# STM32G544 register map
File version: 2.0.0
CPU: CM33 r0p4, little endian, MPU, FPU, 4 interrupt priority bits
Registers are 32-bit, read-write, reset 0x0 unless marked. A register's access mark holds for its fields unless they carry their own. Offsets are from the block's base; [hi:lo] are bit positions; {n}, {i} and the like mark numbered series; 'fields as' and 'values as' point back to an identical list.

## RCC — RCC address block description
Base 0x44020C00
Same registers: RCC_S 0x54020C00
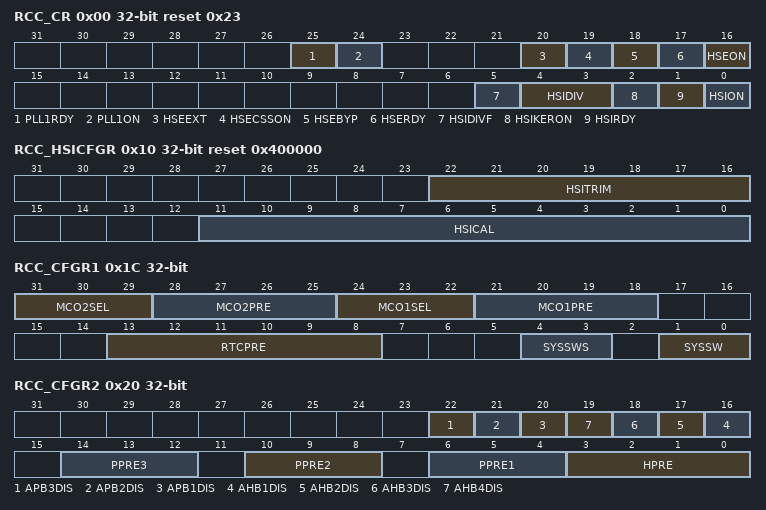
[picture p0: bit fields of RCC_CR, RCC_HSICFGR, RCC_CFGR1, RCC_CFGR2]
0x00 RCC_CR reset 0x23 — RCC clock control register
  [25] PLL1RDY ro — PLL1 clock ready flag
    0=PLL1 unlocked (default after reset); 1=PLL1 locked
  [24] PLL1ON — PLL1 enable
    0=PLL1 OFF (default after reset); 1=PLL1 ON
  [20] HSEEXT — external high speed clock type in Bypass mode
    0=HSE in analog mode (default after reset); 1=HSE in digital mode
  [19] HSECSSON — HSE clock security system enable
    0=CSS on HSE OFF (clock detector OFF) (default after reset); 1=CSS on HSE ON (clock detector ON if the HSE oscillator is stable, OFF if not)
  [18] HSEBYP — HSE clock bypass
    0=HSE oscillator not bypassed (default after reset); 1=HSE oscillator bypassed with an external clock
  [17] HSERDY ro — HSE clock ready flag
    0=HSE clock is not ready (default after reset); 1=HSE clock is ready
  [16] HSEON — HSE clock enable
    0=HSE is OFF (default after reset); 1=HSE is ON
  [5] HSIDIVF ro — HSI divider flag
    0=new division ratio not yet propagated to hsi_ck , hsi_ker_ck (default after reset); 1=hsi_ck, hsi_ker_ck clock frequency reflects the new HSIDIV value (default register value when the clock setting is completed)
  [4:3] HSIDIV — HSI clock divider
    0=division by 1, hsi_ck, hsi_ker_ck = 64 MHz (default after reset); 1=division by 2, hsi_ck, hsi_ker_ck = 32 MHz; 2=division by 4, hsi_ck, hsi_ker_ck = 16 MHz; 3=division by 8, hsi_ck, hsi_ker_ck = 8 MHz
  [2] HSIKERON — HSI clock enable in Stop mode
    0=no effect on HSI (default after reset); 1=HSI is forced to ON even in Stop mode
  [1] HSIRDY ro — HSI clock ready flag
    0=HSI clock is not ready (default after reset); 1=HSI clock is ready
  [0] HSION — HSI clock enable
    0=HSI is OFF; 1=HSI is ON (default after reset)
0x10 RCC_HSICFGR reset 0x400000 (reset mask 0xFFFFF000) — RCC HSI calibration register
  [22:16] HSITRIM — HSI clock trimming
  [11:0] HSICAL ro — HSI clock calibration
0x1C RCC_CFGR1 — RCC clock configuration register1
  [31:29] MCO2SEL — microcontroller clock output 2
    0=system clock selected (sys_ck) (default after reset); 1=PLL2 oscillator clock selected (pll2_p_ck); 2=HSE clock selected (hse_ck); 3=PLL1 clock selected (pll1_p_ck); 4=LSI clock selected (lsi_ck)
  [28:25] MCO2PRE — MCO2 prescaler
    0=prescaler disabled, no clock output on MCO2 (default after reset); 1=division by 1 (bypass); 2=division by 2; 3=division by 3; 4=division by 4; 15=division by 15
  [24:22] MCO1SEL — Microcontroller clock output 1
    0=HSI clock selected (hsi_ck) (default after reset); 1=LSE oscillator clock selected (lse_ck); 2=HSE clock selected (hse_ck); 3=PLL1 clock selected (pll1_q_ck); 4=HSI48 clock selected (hsi48_ker_ck)
  [21:18] MCO1PRE — MCO1 prescaler
    0=prescaler disabled, no clock output on MCO1 (default after reset); 1=division by 1 (bypass); 2=division by 2; 3=division by 3; 4=division by 4; 15=division by 15
  [13:8] RTCPRE — HSE division factor for RTC clock
    0=no clock (default after reset); 1=no clock; 2=HSE/2; 3=HSE/3; 4=HSE/4; 62=HSE/62; 63=HSE/63
  [4:3] SYSSWS ro — system clock switch status
    0=HSI used as system clock (hsi_ck) (default after reset); 1=HSE used as system clock (hse_ck); 2=PLL1 used as system clock (pll1_p_ck)
  [1:0] SYSSW — system clock and trace clock switch
    0=HSI selected as system clock (hsi_ck) (default after reset); 1=HSE selected as system clock (hse_ck); 2=PLL1 selected as system clock (pll1_p_ck)
0x20 RCC_CFGR2 — RCC CPU domain clock configuration register 2
  [22] APB3DIS — APB3 clock disable value.
    0=APB3 clock enabled, distributed to peripherals according to their dedicated clock enable control bits; 1=APB3 clock disabled
  [21] APB2DIS — APB2 clock disable value
    0=APB2 clock enabled, distributed to peripherals according to their dedicated clock enable control bits; 1=APB2 clock disabled
  [20] APB1DIS — APB1 clock disable value
    0=APB1 clock enabled, distributed to peripherals according to their dedicated clock enable control bits; 1=APB1 clock disabled
  [n+15] AHB{n}DIS (n=1..4) — AHB{n} clock disable
    0=AHB{n} clock enabled, distributed to peripherals according to their dedicated clock enable control bits; 1=AHB{n} clock disabled
  [14:12] PPRE3 — APB low-speed prescaler (APB3)
    4=rcc_pclk3 = rcc_hclk1 / 2; 5=rcc_pclk3 = rcc_hclk1 / 4; 6=rcc_pclk3 = rcc_hclk1 / 8; 7=rcc_pclk3 = rcc_hclk1 / 16
  [10:8] PPRE2 — APB high-speed prescaler (APB2)
    4=rcc_pclk2 = rcc_hclk1 / 2; 5=rcc_pclk2 = rcc_hclk1 / 4; 6=rcc_pclk2 = rcc_hclk1 / 8; 7=rcc_pclk2 = rcc_hclk1 / 16
  [6:4] PPRE1 — APB low-speed prescaler (APB1)
    4=rcc_pclk1 = rcc_hclk1 / 2; 5=rcc_pclk1 = rcc_hclk1 / 4; 6=rcc_pclk1 = rcc_hclk1 / 8; 7=rcc_pclk1 = rcc_hclk1 / 16
  [3:0] HPRE — AHB prescaler
    8=rcc_hclk = sys_ck / 2; 9=rcc_hclk = sys_ck / 4; 10=rcc_hclk = sys_ck / 8; 11=rcc_hclk = sys_ck / 16; 12=rcc_hclk = sys_ck / 64; 13=rcc_hclk = sys_ck / 128; 14=rcc_hclk = sys_ck / 256; 15=rcc_hclk = sys_ck / 512
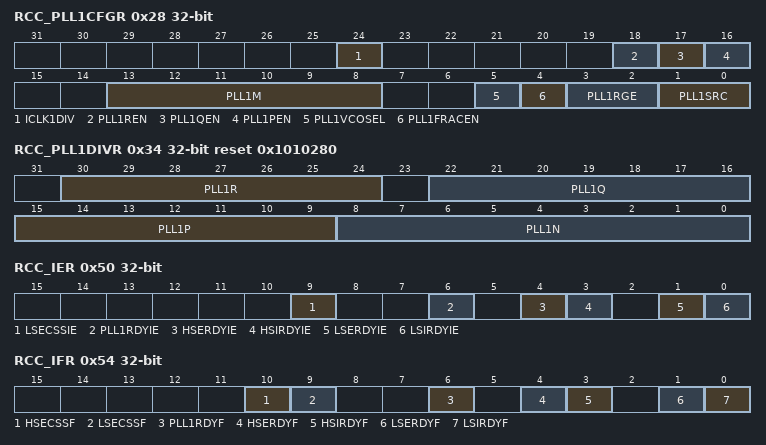
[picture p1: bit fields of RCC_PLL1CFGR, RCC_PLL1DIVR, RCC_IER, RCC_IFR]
0x28 RCC_PLL1CFGR — RCC PLL clock source selection register
  [24] ICLK1DIV — Intermediate Clock 1 division
    0=Intermediate clock 1 division ratio is 5 (default after reset); 1=Intermediate clock 1 division ratio is 3
  [18] PLL1REN — PLL1 DIVR and ICLK1 divider output enable
    0=pll1_r_ck and ic1_ck outputs disabled (default after reset); 1=pll1_r_ck and ic1_ck outputs enabled
  [17] PLL1QEN — PLL1 DIVQ divider output enable
    0=pll1_q_ck output disabled (default after reset); 1=pll1_q_ck output enabled
  [16] PLL1PEN — PLL1 DIVP divider output enable
    0=pll1_p_ck output disabled (default after reset); 1=pll1_p_ck output enabled
  [13:8] PLL1M — prescaler for PLL1
    0=prescaler disabled (default after reset); 1=division by 1 (bypass); 2=division by 2; 3=division by 3; 32=division by 32; 63=division by 63
  [5] PLL1VCOSEL — PLL1 VCO selection
    0=wide VCO range: 128 to 560 MHz (default after reset); 1=medium VCO range: 150 to 420 MHz
  [4] PLL1FRACEN — PLL1 fractional latch enable
  [3:2] PLL1RGE — PLL1 input frequency range
    0=PLL1 input (ref1_ck) clock range frequency between 1 and 2 MHz (default after reset); 1=PLL1 input (ref1_ck) clock range frequency between 2 and 4 MHz; 2=PLL1 input (ref1_ck) clock range frequency between 4 and 8 MHz; 3=PLL1 input (ref1_ck) clock range frequency between 8 and 16 MHz
  [1:0] PLL1SRC — PLL1M and PLLs clock source selection
    0=no clock sent to PLL1M divider and PLL1 (default after reset); 1=HSI selected as PLL clock (hsi_ck); 2=HSE selected as PLL clock (hse_ck); 3=no clock sent to PLL1M divider and PLL1
0x34 RCC_PLL1DIVR reset 0x1010280 — RCC PLL1 dividers register
  [30:24] PLL1R — PLL1 DIVR division factor
    0=pll1_r_ck = vco1_ck / 1; 1=pll1_r_ck = vco1_ck / 2 (default after reset); 2=pll1_r_ck = vco1_ck / 3; 3=pll1_r_ck = vco1_ck / 4; 127=pll1_r_ck = vco1_ck / 128
  [22:16] PLL1Q — PLL1 DIVQ division factor
    0=pll1_q_ck = vco1_ck; 1=pll1_q_ck = vco1_ck / 2 (default after reset); 2=pll1_q_ck = vco1_ck / 3; 3=pll1_q_ck = vco1_ck / 4; 127=pll1_q_ck = vco1_ck / 128
  [15:9] PLL1P — PLL1 DIVP division factor
    0=Not allowed; 1=pll1_p_ck = vco1_ck / 2 (default after reset); 2=Not allowed; 3=pll1_p_ck = vco1_ck / 4; 127=pll1_p_ck = vco1_ck / 128
  [8:0] PLL1N — Multiplication factor for PLL1VCO
    3=PLL1N = 4; 4=PLL1N = 5; 5=PLL1N = 6; 128=PLL1N = 129 (default after reset); 0x1FF=PLL1N = 512
0x38 RCC_PLL1FRACR — RCC PLL1 fractional divider register
  [15:3] PLL1FRACN — fractional part of the multiplication factor for PLL1 VCO
0x50 RCC_IER — RCC Interrupt enable register
  [9] LSECSSIE — LSE clock security system interrupt enable
    0=LSE CSS interrupt disabled (default after reset); 1=LSE CSS interrupt enabled
  [6] PLL1RDYIE — PLL1 ready interrupt enable
    0=PLL1 lock interrupt disabled (default after reset); 1=PLL1 lock interrupt enabled
  [4] HSERDYIE — HSE ready interrupt enable
    0=HSE ready interrupt disabled (default after reset); 1=HSE ready interrupt enabled
  [3] HSIRDYIE — HSI ready interrupt enable
    0=HSI ready interrupt disabled (default after reset); 1=HSI ready interrupt enabled
  [1] LSERDYIE — LSE ready interrupt enable
    0=LSE ready interrupt disabled (default after reset); 1=LSE ready interrupt enabled
  [0] LSIRDYIE — LSI ready interrupt enable
    0=LSI ready interrupt disabled (default after reset); 1=LSI ready interrupt enabled
0x54 RCC_IFR ro — RCC Interrupt flag register
  [10] HSECSSF — HSE clock security system interrupt flag
    0=no clock security interrupt caused by HSE clock failure (default after reset); 1=clock security interrupt caused by HSE clock failure
  [9] LSECSSF — LSE clock security system interrupt flag
    values as HSECSSF
  [6] PLL1RDYF — PLL1 ready interrupt flag
    0=no clock ready interrupt caused by PLL1 lock (default after reset); 1=clock ready interrupt caused by PLL1 lock
  [4] HSERDYF — HSE ready interrupt flag
    0=no clock ready interrupt caused by the HSE (default after reset); 1=clock ready interrupt caused by the HSE
  [3] HSIRDYF — HSI ready interrupt flag
    0=no clock ready interrupt caused by the HSI (default after reset); 1=clock ready interrupt caused by the HSI
  [1] LSERDYF — LSE ready interrupt flag
    0=no clock ready interrupt caused by the LSE (default after reset); 1=clock ready interrupt caused by the LSE
  [0] LSIRDYF — LSI ready interrupt flag
    0=no clock ready interrupt caused by the LSI (default after reset); 1=clock ready interrupt caused by the LSI
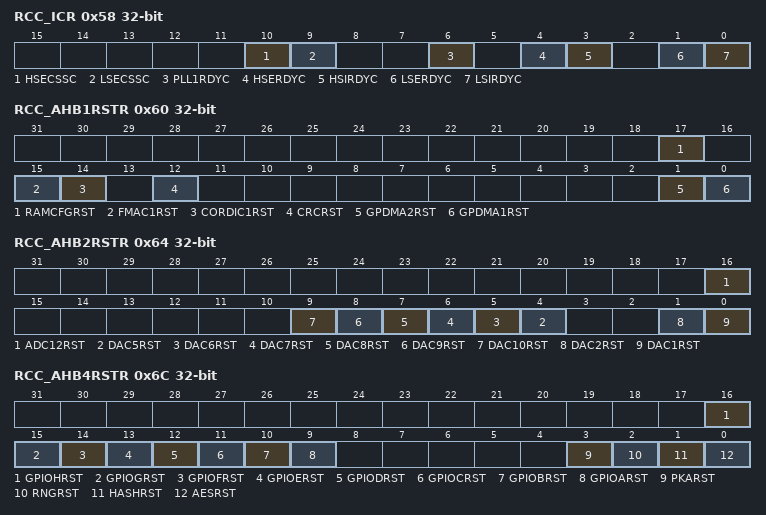
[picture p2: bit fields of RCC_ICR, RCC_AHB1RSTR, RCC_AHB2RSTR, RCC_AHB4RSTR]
0x58 RCC_ICR — RCC Interrupt clear register
  [10] HSECSSC — HSE clock security system interrupt clear
    0=HSECSSF no effect (default after reset); 1=HSECSSF cleared
  [9] LSECSSC — LSE clock security system interrupt clear
    0=LSECSSF no effect (default after reset); 1=LSECSSF cleared
  [6] PLL1RDYC — PLL1 ready interrupt clear
    0=PLL1RDYF no effect (default after reset); 1=PLL1RDYF cleared
  [4] HSERDYC — HSE ready interrupt clear
    0=HSERDYF no effect (default after reset); 1=HSERDYF cleared
  [3] HSIRDYC — HSI ready interrupt clear
    0=HSIRDYF no effect (default after reset); 1=HSIRDYF cleared
  [1] LSERDYC — LSE ready interrupt clear
    0=LSERDYF no effect (default after reset); 1=LSERDYF cleared
  [0] LSIRDYC — LSI ready interrupt clear
    0=LSIRDYF no effect (default after reset); 1=LSIRDYF cleared
0x60 RCC_AHB1RSTR — RCC AHB1 reset register
  [17] RAMCFGRST — RAMCFG block reset
    0=does not reset RAMCFG block (default after reset); 1=resets RAMCFG block
  [15] FMAC1RST — FMAC1 block reset
    0=does not reset FMAC1 block (default after reset); 1=resets FMAC1 block
  [14] CORDIC1RST — CORDIC1 block reset
    0=does not reset CORDIC1 block (default after reset); 1=resets CORDIC1 block
  [12] CRCRST — CRC block reset Set and cleared by software.
    0=does not reset CRC block (default after reset); 1=resets CRC block
  [1] GPDMA2RST — GPDMA2 block reset
    0=does not reset GPDMA2 block (default after reset); 1=resets GPDMA2 block
  [0] GPDMA1RST — GPDMA1 block reset
    0=does not reset GPDMA1 block (default after reset); 1=resets GPDMA1 block
0x64 RCC_AHB2RSTR — RCC AHB2 peripheral reset register
  [16] ADC12RST — ADC1 and 2 blocks reset
    0=does not reset ADC1 and 2 blocks (default after reset); 1=resets ADC1 and 2 blocks
  [n-1] DAC{n}RST (n=5..10) — DAC{n} block reset
    0=does not reset DAC{n} block (default after reset); 1=resets DAC{n} block
  [1] DAC2RST — DAC2 block reset
    0=does not reset DAC2 block (default after reset); 1=resets DAC2 block
  [0] DAC1RST — DAC1 block reset
    0=does not reset DAC1 block (default after reset); 1=resets DAC1 block
0x6C RCC_AHB4RSTR — RCC AHB4 peripheral reset register
  [16] GPIOHRST — GPIOH block reset
    0=does not reset the GPIOH block (default after reset); 1=resets the GPIOH block
  [15] GPIOGRST — GPIOG block reset
    0=does not reset the GPIOG block (default after reset); 1=resets the GPIOG block
  [14] GPIOFRST — GPIOF block reset
    0=does not reset the GPIOF block (default after reset); 1=resets the GPIOF block
  [13] GPIOERST — GPIOE block reset
    0=does not reset the GPIOE block (default after reset); 1=resets the GPIOE block
  [12] GPIODRST — GPIOD block reset
    0=does not reset the GPIOD block (default after reset); 1=resets the GPIOD block
  [11] GPIOCRST — GPIOC block reset
    0=does not reset the GPIOC block (default after reset); 1=resets the GPIOC block
  [10] GPIOBRST — GPIOB block reset
    0=does not reset the GPIOB block (default after reset); 1=resets the GPIOB block
  [9] GPIOARST — GPIOA block reset
    0=does not reset the GPIOA block (default after reset); 1=resets the GPIOA block
  [3] PKARST — PKA block reset
    0=does not reset PKA block (default after reset); 1=resets PKA block
  [2] RNGRST — RNG block reset
    0=does not reset RNG block (default after reset); 1=resets RNG block
  [1] HASHRST — HASH block reset
    0=does not reset HASH block (default after reset); 1=resets HASH block
  [0] AESRST — AES block reset
    0=does not reset AES block (default after reset); 1=resets AES block
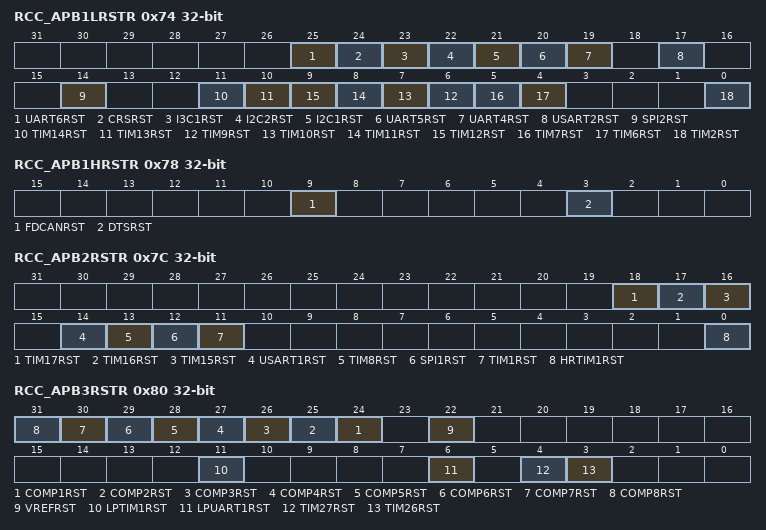
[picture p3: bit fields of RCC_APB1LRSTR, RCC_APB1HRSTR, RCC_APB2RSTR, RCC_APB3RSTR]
0x74 RCC_APB1LRSTR — RCC APB1 peripheral low reset register
  [25] UART6RST — UART6 block reset
    0=does not reset the UART6 block (default after reset); 1=resets the UART6 block
  [24] CRSRST — CRS block reset
    0=does not reset the CRS block (default after reset); 1=resets the CRS block
  [23] I3C1RST — I3C1 block reset
    0=does not reset the I3C1 block (default after reset); 1=resets the I3C1 block
  [22] I2C2RST — I2C2 block reset
    0=does not reset the I2C2 block (default after reset); 1=resets the I2C2 block
  [21] I2C1RST — I2C1 block reset
    0=does not reset the I2C1 block (default after reset); 1=resets the I2C1 block
  [20] UART5RST — UART5 block reset
    0=does not reset the UART5 block (default after reset); 1=resets the UART5 block
  [19] UART4RST — UART4 block reset
    0=does not reset the UART4 block (default after reset); 1=resets the UART4 block
  [17] USART2RST — USART2 block reset
    0=does not reset the USART2 block (default after reset); 1=resets the USART2 block
  [14] SPI2RST — SPI2 block reset
    0=does not reset the SPI2 block (default after reset); 1=resets the SPI2 block
  [11] TIM14RST — TIM14 block reset
    0=does not reset the TIM14 block (default after reset); 1=resets the TIM14 block
  [10] TIM13RST — TIM13 block reset
    0=does not reset the TIM13 block (default after reset); 1=resets the TIM13 block
  [n-3] TIM{n}RST (n=9..12) — TIM12 block reset
    0=does not reset the TIM12 block (default after reset); 1=resets the TIM12 block
  [5] TIM7RST — TIM7 block reset
    0=does not reset the TIM7 block (default after reset); 1=resets the TIM7 block
  [4] TIM6RST — TIM6 block reset
    0=does not reset the TIM6 block (default after reset); 1=resets the TIM6 block
  [0] TIM2RST — TIM2 block reset
    0=does not reset the TIM2 block (default after reset); 1=resets the TIM2 block
0x78 RCC_APB1HRSTR — RCC APB1 peripheral high reset register
  [9] FDCANRST — FDCAN1, FDCAN2 and FDCAN3 blocks reset
    0=does not reset the FDCAN1, FDCAN2 and FDCAN3 blocks (default after reset); 1=resets the FDCAN1, FDCAN2 and FDCAN3 blocks
  [3] DTSRST — DTS block reset
    0=does not reset the DTS block (default after reset); 1=resets the DTS block
0x7C RCC_APB2RSTR — RCC APB2 peripheral reset register
  [18] TIM17RST — TIM17 block reset
    0=does not reset the TIM17 block (default after reset); 1=resets the TIM17 block
  [17] TIM16RST — TIM16 block reset
    0=does not reset the TIM16 block (default after reset); 1=resets the TIM16 block
  [16] TIM15RST — TIM15 block reset
    0=does not reset the TIM15 block (default after reset); 1=resets the TIM15 block
  [14] USART1RST — USART1 block reset
    0=does not reset the USART1 block (default after reset); 1=resets the USART1 block
  [13] TIM8RST — TIM8 block reset
    0=does not reset the TIM8 block (default after reset); 1=resets the TIM8 block
  [12] SPI1RST — SPI1 block reset
    0=does not reset the SPI1 block (default after reset); 1=resets the SPI1 block
  [11] TIM1RST — TIM1 block reset
    0=does not reset the TIM1 block (default after reset); 1=resets the TIM1 block
  [0] HRTIM1RST — HRTIM1 block reset
    0=does not reset the HRTIM1 block (default after reset); 1=resets the HRTIM1 block
0x80 RCC_APB3RSTR — RCC APB3 peripheral reset register
  [n+23] COMP{n}RST (n=1..8) — COMP{n} block reset
    0=does not reset the COMP{n} block (default after reset); 1=resets the COMP{n} block
  [22] VREFRST — VREFBUF block reset
    0=does not reset the VREFBUF block (default after reset); 1=resets the VREFBUF block
  [11] LPTIM1RST — LPTIM1 block reset
    0=does not reset the LPTIM1 block (default after reset); 1=resets the LPTIM1 block
  [6] LPUART1RST — LPUART1 block reset
    0=does not reset the LPUART1 block (default after reset); 1=resets the LPUART1 block
  [4] TIM27RST — TIM27 block reset
    0=does not reset the TIM27 block (default after reset); 1=resets the TIM27 block
  [3] TIM26RST — TIM26 block reset
    0=does not reset the TIM26 block (default after reset); 1=resets the TIM26 block
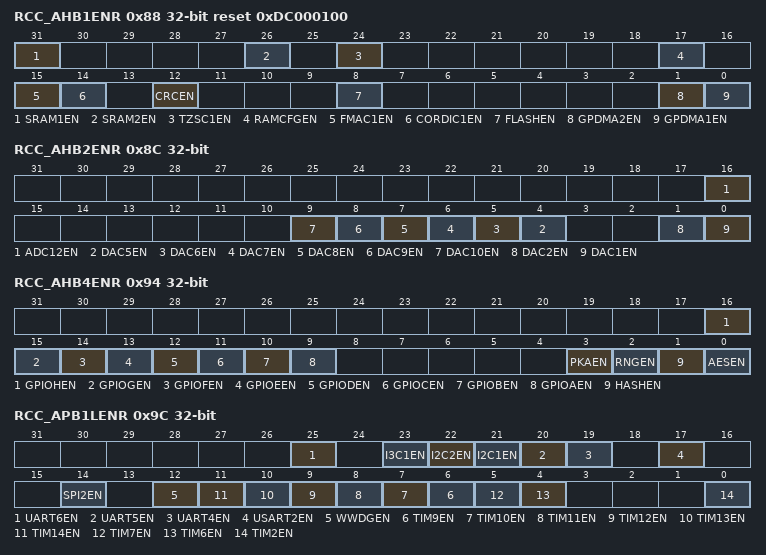
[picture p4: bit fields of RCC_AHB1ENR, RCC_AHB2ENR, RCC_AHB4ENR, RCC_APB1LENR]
0x88 RCC_AHB1ENR reset 0xDC000100 — RCC AHB1 peripheral clock enable register
  [31] SRAM1EN — SRAM1 clock enable
    0=SRAM1 clock disabled; 1=SRAM1 clock enabled (default after reset)
  [26] SRAM2EN — SRAM2 clock enable
    0=SRAM2 clock disabled; 1=SRAM2 clock enabled (default after reset)
  [24] TZSC1EN — TZSC1 clock enable
    0=TZSC1 peripheral clock disabled (default after reset); 1=TZSC1 peripheral clock enabled
  [17] RAMCFGEN — RAMCFG clock enable
    0=RAMCFG peripheral clock disabled (default after reset); 1=RAMCFG peripheral clock enabled
  [15] FMAC1EN — FMAC1 clock enable
    0=FMAC1 peripheral clock disabled (default after reset); 1=FMAC1 peripheral clock enabled
  [14] CORDIC1EN — CORDIC1 clock enable
    0=CORDIC1 peripheral clock disabled (default after reset); 1=CORDIC1 peripheral clock enable
  [12] CRCEN — CRC clock enable
    0=CRC peripheral clock disabled (default after reset); 1=CRC peripheral clock enabled
  [8] FLASHEN — Flash interface clock enable
    0=FLASH interface clock disabled; 1=FLASH interface clock enabled (default after reset)
  [1] GPDMA2EN — GPDMA2 clock enable
    0=GPDMA2 peripheral clock disabled (default after reset); 1=GPDMA2 peripheral clock enabled
  [0] GPDMA1EN — GPDMA1 clock enable
    0=GPDMA1 peripheral clock disabled (default after reset); 1=GPDMA1 peripheral clock enabled
0x8C RCC_AHB2ENR — RCC AHB2 peripheral clock enable register
  [16] ADC12EN — ADC1 and ADC2 peripheral clocks enable
    0=ADC1 and ADC2 peripheral clocks disabled (default after reset); 1=ADC1 and ADC2 peripheral clocks enabled
  [n-1] DAC{n}EN (n=5..10) — DAC{n} clock enable
    0=DAC{n} peripheral clock disabled (default after reset); 1=DAC{n} peripheral clock enabled
  [1] DAC2EN — DAC2 clock enable
    0=DAC2 peripheral clock disabled (default after reset); 1=DAC2 peripheral clock enabled
  [0] DAC1EN — DAC1 clock enable
    0=DAC1 peripheral clock disabled (default after reset); 1=DAC1 peripheral clock enabled
0x90 RCC_AHB3ENR — RCC AHB3 peripheral clock enable register
  [21] DBGCKEN — DBG clock enable
    0=DBG peripheral clock disabled (default after reset); 1=DBG peripheral clock enabled
0x94 RCC_AHB4ENR — RCC AHB4 peripheral clock enable register
  [16] GPIOHEN — GPIOH clock enable
    0=GPIOH peripheral clock disabled (default after reset); 1=GPIOH peripheral clock enabled
  [15] GPIOGEN — GPIOG clock enable
    0=GPIOG peripheral clock disabled (default after reset); 1=GPIOG peripheral clock enabled
  [14] GPIOFEN — GPIOF clock enable
    0=GPIOF peripheral clock disabled (default after reset); 1=GPIOF peripheral clock enabled
  [13] GPIOEEN — GPIOE clock enable
    0=GPIOE peripheral clock disabled (default after reset); 1=GPIOE peripheral clock enabled
  [12] GPIODEN — GPIOD clock enable
    0=GPIOD peripheral clock disabled (default after reset); 1=GPIOD peripheral clock enabled
  [11] GPIOCEN — GPIOC clock enable
    0=GPIOC peripheral clock disabled (default after reset); 1=GPIOC peripheral clock enabled
  [10] GPIOBEN — GPIOB clock enable
    0=GPIOB peripheral clock disabled (default after reset); 1=GPIOB peripheral clock enabled
  [9] GPIOAEN — GPIOA clock enable
    0=GPIOA peripheral clock disabled (default after reset); 1=GPIOA peripheral clock enabled
  [3] PKAEN — PKA clock enable
    0=PKA peripheral clock disabled (default after reset); 1=PKA peripheral clock enabled
  [2] RNGEN — RNG clock enable
    0=RNG peripheral clock disabled (default after reset); 1=RNG peripheral clock enabled
  [1] HASHEN — HASH clock enable
    0=HASH peripheral clock disabled (default after reset); 1=HASH peripheral clock enabled
  [0] AESEN — AES clock enable
    0=AES peripheral clock disabled (default after reset); 1=AES peripheral clock enabled
0x9C RCC_APB1LENR — RCC APB1 peripheral clock enable register
  [25] UART6EN — UART6 clock enable
    0=UART6 peripheral clock disabled (default after reset); 1=UART6 peripheral clock enabled
  [23] I3C1EN — I3C1 clock enable
    0=I3C1 peripheral clock disabled (default after reset); 1=I3C1 peripheral clock enabled
  [22] I2C2EN — I2C2 clock enable
    0=I2C2 peripheral clock disabled (default after reset); 1=I2C2 peripheral clock enabled
  [21] I2C1EN — I2C1 clock enable
    0=I2C1 peripheral clock disabled (default after reset); 1=I2C1 peripheral clock enabled
  [20] UART5EN — UART5 clock enable
    0=UART5 peripheral clock disabled (default after reset); 1=UART5 peripheral clock enabled
  [19] UART4EN — UART4 clock enable
    0=UART4 peripheral clock disabled (default after reset); 1=UART4 peripheral clock enabled
  [17] USART2EN — USART2 clock enable
    0=USART2 peripheral clock disabled (default after reset); 1=USART2 peripheral clock enabled
  [14] SPI2EN — SPI2 clock enable
    0=SPI2 peripheral clock disabled (default after reset); 1=SPI2 peripheral clock enabled
  [12] WWDGEN — WWDG clock enable
    0=WWDG peripheral clock disabled (default after reset); 1=WWDG peripheral clock enabled
  [n-3] TIM{n}EN (n=9..14) — TIM{n} clock enable
    0=TIM{n} peripheral clock disabled (default after reset); 1=TIM{n} peripheral clock enabled
  [5] TIM7EN — TIM7 clock enable
    0=TIM7 peripheral clock disabled (default after reset); 1=TIM7 peripheral clock enabled
  [4] TIM6EN — TIM6 clock enable
    0=TIM6 peripheral clock disabled (default after reset); 1=TIM6 peripheral clock enabled
  [0] TIM2EN — TIM2 clock enable
    0=TIM2 peripheral clock disabled (default after reset); 1=TIM2 peripheral clock enabled
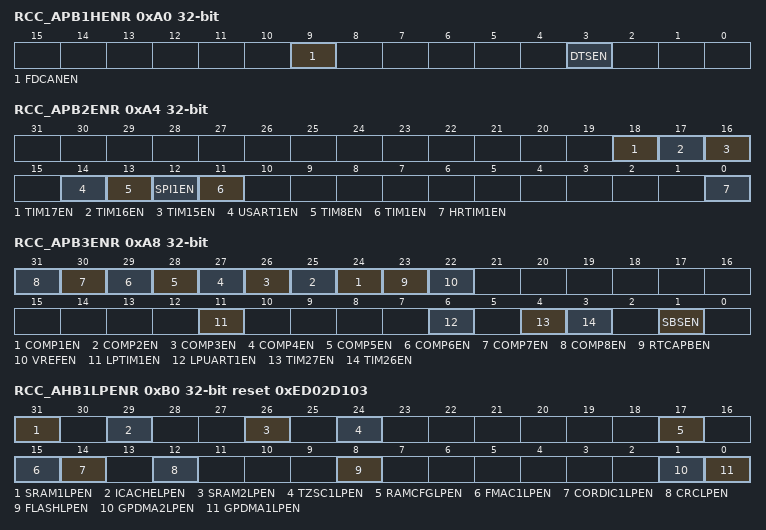
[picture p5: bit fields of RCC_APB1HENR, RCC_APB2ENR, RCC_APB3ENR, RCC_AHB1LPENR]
0xA0 RCC_APB1HENR — RCC APB1 peripheral clock enable register
  [9] FDCANEN — FDCAN1, FDCAN2 and FDCAN3 peripheral clock enable
    0=FDCAN1, FDCAN2 and FDCAN3 peripheral clock disabled (default after reset); 1=FDCAN1, FDCAN2 and FDCAN3 peripheral clock enabled
  [3] DTSEN — DTS clock enable
    0=DTS peripheral clock disabled (default after reset); 1=DTS peripheral clock enabled
0xA4 RCC_APB2ENR — RCC APB2 peripheral clock enable register
  [18] TIM17EN — TIM17 clock enable
    0=TIM17 peripheral clock disabled (default after reset); 1=TIM17 peripheral clock enabled
  [17] TIM16EN — TIM16 clock enable
    0=TIM16 peripheral clock disabled (default after reset); 1=TIM16 peripheral clock enabled
  [16] TIM15EN — TIM15 clock enable
    0=TIM15 peripheral clock disabled (default after reset); 1=TIM15 peripheral clock enabled
  [14] USART1EN — USART1 clock enable
    0=USART1 peripheral clock disabled (default after reset); 1=USART1 peripheral clock enabled
  [13] TIM8EN — TIM8 clock enable
    0=TIM8 peripheral clock disabled (default after reset); 1=TIM8 peripheral clock enabled
  [12] SPI1EN — SPI1 clock enable
    0=SPI1 peripheral clock disabled (default after reset); 1=SPI1 peripheral clock enabled
  [11] TIM1EN — TIM1 clock enable
    0=TIM1 peripheral clock disabled (default after reset); 1=TIM1 peripheral clock enabled
  [0] HRTIM1EN — HRTIM1 clock enable
    0=HRTIM1 peripheral clock disabled (default after reset); 1=HRTIM1 peripheral clock enabled
0xA8 RCC_APB3ENR — RCC APB3 peripheral clock enable register
  [n+23] COMP{n}EN (n=1..8) — COMP{n} clock enable
    0=COMP{n} clock disabled (default after reset); 1=COMP{n} clock enabled
  [23] RTCAPBEN — RTC APB interface clock enable
    0=RTC APB interface clock disabled (default after reset); 1=RTC APB interface clock enabled
  [22] VREFEN — VREFBUF clock enable
    0=VREFBUF peripheral clock disabled (default after reset); 1=VREFBUF peripheral clock enabled
  [11] LPTIM1EN — LPTIM1 clock enable
    0=LPTIM1 peripheral clock disabled (default after reset); 1=LPTIM1 peripheral clock enabled
  [6] LPUART1EN — LPUART1 clock enable
    0=LPUART1 peripheral clock disabled (default after reset); 1=LPUART1 peripheral clock enabled
  [4] TIM27EN — TIM27 clock enable
    0=TIM27 peripheral clock disabled (default after reset); 1=TIM27 peripheral clock enabled
  [3] TIM26EN — TIM26 clock enable
    0=TIM26 peripheral clock disabled (default after reset); 1=TIM26 peripheral clock enabled
  [1] SBSEN — SBS clock enable
    0=SBS peripheral clock disabled (default after reset); 1=SBS peripheral clock enabled
0xB0 RCC_AHB1LPENR reset 0xED02D103 — RCC AHB1 peripheral low-power clock enable register
  [31] SRAM1LPEN — SRAM1 clock enable in low power mode
    0=SRAM1 peripheral clock disabled in low power mode; 1=SRAM1 peripheral clock enabled in low power mode (default after reset)
  [29] ICACHELPEN — ICACHE clock enable in low power mode
    0=ICACHE peripheral clock disabled in low power mode; 1=ICACHE peripheral clock enabled in low power mode (default after reset)
  [26] SRAM2LPEN — SRAM2 clock enable in low power mode
    0=SRAM2 peripheral clock disabled in low power mode; 1=SRAM2 peripheral clock enabled in low power mode (default after reset)
  [24] TZSC1LPEN — TZSC1 clock enable in low power mode
    0=TZSC1 peripheral clock disabled in low power mode; 1=TZSC1 peripheral clock enabled in low power mode (default after reset)
  [17] RAMCFGLPEN — RAMCFG clock enable in low power mode
    0=RAMCFG peripheral clock disabled in low power mode; 1=RAMCFG peripheral clock enabled in low power mode (default after reset)
  [15] FMAC1LPEN — FMAC1 clock enable in low power mode
    0=FMAC1 peripheral clock disabled in low power mode; 1=FMAC1 peripheral clock enabled in low power mode (default after reset)
  [14] CORDIC1LPEN — CORDIC1 clock enable in low power mode
    0=CORDIC1 peripheral clock disabled in low power mode; 1=CORDIC1 peripheral clock enabled in low power mode (default after reset)
  [12] CRCLPEN — CRC clock enable in low power mode
    0=CRC peripheral clock disabled in low power mode; 1=CRC peripheral clock enabled in low power mode (default after reset)
  [8] FLASHLPEN — Flash memory interface clock enable in low-power mode
    0=Flash memory interface clock disabled in low power mode; 1=Flash memory interface clock enabled in low power mode (default after reset)
  [1] GPDMA2LPEN — GPDMA2 clock enable in low power mode
    0=GPDMA2 peripheral clock disabled in low power mode; 1=GPDMA2 peripheral clock enabled in low power mode (default after reset)
  [0] GPDMA1LPEN — GPDMA1 clock enable in low power mode
    0=GPDMA1 peripheral clock disabled in low power mode; 1=GPDMA1 peripheral clock enabled in low power mode (default after reset)
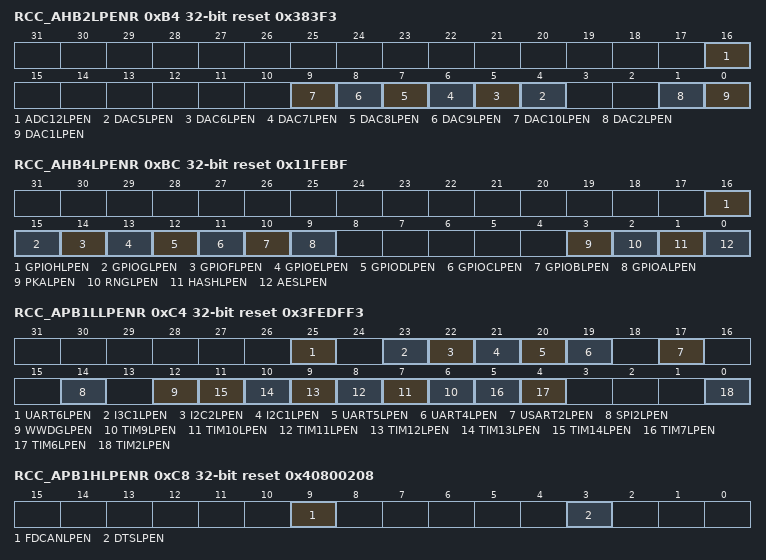
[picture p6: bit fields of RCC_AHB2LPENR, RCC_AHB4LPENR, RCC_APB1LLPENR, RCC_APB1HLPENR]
0xB4 RCC_AHB2LPENR reset 0x383F3 — RCC AHB2 peripheral low-power clock enable register
  [16] ADC12LPEN — ADC1 and 2 peripherals clock enable in low power mode
    0=ADC1 and 2 peripherals clock disabled in low power mode; 1=ADC1 and 2 peripherals clock enabled in low power mode (default after reset)
  [n-1] DAC{n}LPEN (n=5..10) — DAC{n} clock enable in low power mode
    0=DAC{n} peripheral clock disabled in low power mode; 1=DAC{n} peripheral clock enabled in low power mode (default after reset)
  [1] DAC2LPEN — DAC2 clock enable in low power mode
    0=DAC2 peripheral clock disabled in low power mode; 1=DAC2 peripheral clock enabled in low power mode (default after reset)
  [0] DAC1LPEN — DAC1 clock enable in low power mode
    0=DAC1 peripheral clock disabled in low power mode; 1=DAC1 peripheral clock enabled in low power mode (default after reset)
0xB8 RCC_AHB3LPENR reset 0x200000 — RCC AHB3 peripheral low-power clock enable register
  [21] DBGCKLPEN — DBG clock enable in low power mode
    0=DBG peripheral clock disabled in low power mode; 1=DBG peripheral clock enabled in low power mode (default after reset)
0xBC RCC_AHB4LPENR reset 0x11FEBF — RCC AHB4 peripheral low-power clock enable register
  [16] GPIOHLPEN — GPIOH clock enable in low power mode
    0=GPIOH peripheral clock disabled in low power mode; 1=GPIOH peripheral clock enabled in low power mode (default after reset)
  [15] GPIOGLPEN — GPIOG clock enable in low power mode
    0=GPIOG peripheral clock disabled in low power mode; 1=GPIOG peripheral clock enabled in low power mode (default after reset)
  [14] GPIOFLPEN — GPIOF clock enable in low power mode
    0=GPIOF peripheral clock disabled in low power mode; 1=GPIOF peripheral clock enabled in low power mode (default after reset)
  [13] GPIOELPEN — GPIOE clock enable in low power mode
    0=GPIOE peripheral clock disabled in low power mode; 1=GPIOE peripheral clock enabled in low power mode (default after reset)
  [12] GPIODLPEN — GPIOD clock enable in low power mode
    0=GPIOD peripheral clock disabled in low power mode; 1=GPIOD peripheral clock enabled in low power mode (default after reset)
  [11] GPIOCLPEN — GPIOC clock enable in low power mode
    0=GPIOC peripheral clock disabled in low power mode; 1=GPIOC peripheral clock enabled in low power mode (default after reset)
  [10] GPIOBLPEN — GPIOB clock enable in low power mode
    0=GPIOB peripheral clock disabled in low power mode; 1=GPIOB peripheral clock enabled in low power mode (default after reset)
  [9] GPIOALPEN — GPIOA clock enable in low power mode
    0=GPIOA peripheral clock disabled in low power mode; 1=GPIOA peripheral clock enabled in low power mode (default after reset)
  [3] PKALPEN — PKA clock enable in low power mode
    0=PKA peripheral clock disabled in low power mode; 1=PKA peripheral clock enabled in low power mode (default after reset)
  [2] RNGLPEN — RNG clock enable in low power mode
    0=RNG peripheral clock disabled in low power mode; 1=RNG peripheral clock enabled in low power mode (default after reset)
  [1] HASHLPEN — HASH clock enable in low power mode
    0=HASH peripheral clock disabled in low power mode; 1=HASH peripheral clock enabled in low power mode (default after reset)
  [0] AESLPEN — AES clock enable in low power mode
    0=AES peripheral clock disabled in low power mode; 1=AES peripheral clock enabled in low power mode (default after reset)
0xC4 RCC_APB1LLPENR reset 0x3FEDFF3 — RCC APB1 peripheral low-power clock enable register
  [25] UART6LPEN — UART6 clock enable in low power mode
    0=UART6 peripheral clock disabled in low power mode; 1=UART6 peripheral clock enabled in low power mode (default after reset)
  [23] I3C1LPEN — I3C1 clock enable in low power mode
    0=I3C1 peripheral clock disabled in low power mode; 1=I3C1 peripheral clock enabled in low power mode (default after reset)
  [22] I2C2LPEN — I2C2 clock enable in low power mode
    0=I2C2 peripheral clock disabled in low power mode; 1=I2C2 peripheral clock enabled in low power mode (default after reset)
  [21] I2C1LPEN — I2C1 clock enable in low power mode
    0=I2C1 peripheral clock disabled in low power mode; 1=I2C1 peripheral clock enabled in low power mode (default after reset)
  [20] UART5LPEN — UART5 clock enable in low power mode
    0=UART5 peripheral clock disabled in low power mode; 1=UART5 peripheral clock enabled in low power mode (default after reset)
  [19] UART4LPEN — UART4 clock enable in low power mode
    0=UART4 peripheral clock disabled in low power mode; 1=UART4 peripheral clock enabled in low power mode (default after reset)
  [17] USART2LPEN — USART2 clock enable in low power mode
    0=USART2 peripheral clock disabled in low power mode; 1=USART2 peripheral clock enabled in low power mode (default after reset)
  [14] SPI2LPEN — SPI2 clock enable in low power mode
    0=SPI2 peripheral clock disabled in low power mode; 1=SPI2 peripheral clock enabled in low power mode (default after reset)
  [12] WWDGLPEN — WWDG clock enable in low power mode
    0=WWDG peripheral clock disabled in low power mode; 1=WWDG peripheral clock enabled in low power mode (default after reset)
  [n-3] TIM{n}LPEN (n=9..14) — TIM{n} clock enable in low power mode
    0=TIM{n} peripheral clock disabled in low power mode; 1=TIM{n} peripheral clock enabled in low power mode (default after reset)
  [5] TIM7LPEN — TIM7 clock enable in low power mode
    0=TIM7 peripheral clock disabled in low power mode; 1=TIM7 peripheral clock enabled in low power mode (default after reset)
  [4] TIM6LPEN — TIM6 clock enable in low power mode
    0=TIM6 peripheral clock disabled in low power mode; 1=TIM6 peripheral clock enabled in low power mode (default after reset)
  [0] TIM2LPEN — TIM2 clock enable in low power mode
    0=TIM2 peripheral clock disabled in low power mode; 1=TIM2 peripheral clock enabled in low power mode (default after reset)
0xC8 RCC_APB1HLPENR reset 0x40800208 — RCC APB1 peripheral low-power clock enable register
  [9] FDCANLPEN — FDCAN1, FDCAN2 and FDCAN3 peripheral clock enable in low power mode
    0=FDCAN1, FDCAN2 and FDCAN3 peripheral clock disabled in low power mode; 1=FDCAN1, FDCAN2 and FDCAN3 peripheral clock enabled in low power mode (default after reset)
  [3] DTSLPEN — DTS clock enable in low power mode
    0=DTS peripheral clock disabled in low power mode; 1=DTS peripheral clock enabled in low power mode (default after reset)
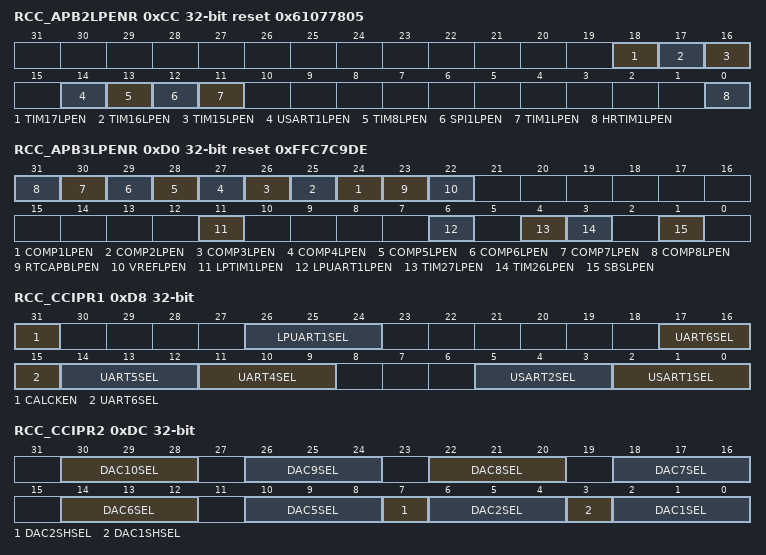
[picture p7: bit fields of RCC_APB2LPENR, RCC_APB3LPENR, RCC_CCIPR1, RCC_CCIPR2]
0xCC RCC_APB2LPENR reset 0x61077805 — RCC APB2 peripheral low-power clock enable register
  [18] TIM17LPEN — TIM17 clock enable in low power mode
    0=TIM17 peripheral clock disabled in low power mode; 1=TIM17 peripheral clock enabled in low power mode (default after reset)
  [17] TIM16LPEN — TIM16 clock enable in low power mode
    0=TIM16 peripheral clock disabled in low power mode; 1=TIM16 peripheral clock enabled in low power mode (default after reset)
  [16] TIM15LPEN — TIM15 clock enable in low power mode
    0=TIM15 peripheral clock disabled in low power mode; 1=TIM15 peripheral clock enabled in low power mode (default after reset)
  [14] USART1LPEN — USART1 clock enable in low power mode
    0=USART1 peripheral clock disabled in low power mode; 1=USART1 peripheral clock enabled in low power mode (default after reset)
  [13] TIM8LPEN — TIM8 clock enable in low power mode
    0=TIM8 peripheral clock disabled in low power mode; 1=TIM8 peripheral clock enabled in low power mode (default after reset)
  [12] SPI1LPEN — SPI1 clock enable in low power mode
    0=SPI1 peripheral clock disabled in low power mode; 1=SPI1 peripheral clock enabled in low power mode (default after reset)
  [11] TIM1LPEN — TIM1 clock enable in low power mode
    0=TIM1 peripheral clock disabled in low power mode; 1=TIM1 peripheral clock enabled in low power mode (default after reset)
  [0] HRTIM1LPEN — HRTIM1 clock enable in low power mode
    0=HRTIM1 peripheral clock disabled in low power mode; 1=HRTIM1 peripheral clock enabled in low power mode (default after reset)
0xD0 RCC_APB3LPENR reset 0xFFC7C9DE — RCC APB3 peripheral low-power clock enable register
  [n+23] COMP{n}LPEN (n=1..8) — COMP{n} clock enable in low power mode
    0=COMP{n} peripheral clock disabled in low power mode; 1=COMP{n} peripheral clock enabled in low power mode (default after reset)
  [23] RTCAPBLPEN — RTC APB interface clock enable in low power mode
    0=RTC APB interface clock disabled in low power mode; 1=RTC APB interface clock enabled in low power mode (default after reset)
  [22] VREFLPEN — VREFBUF clock enable in low power mode
    0=VREFBUF peripheral clock disabled in low power mode; 1=VREFBUF peripheral clock enabled in low power mode (default after reset)
  [11] LPTIM1LPEN — LPTIM1 clock enable in low power mode
    0=LPTIM1 peripheral clock disabled in low power mode; 1=LPTIM1 peripheral clock enabled in low power mode (default after reset)
  [6] LPUART1LPEN — LPUART1 clock enable in low power mode
    0=LPUART1 peripheral clock disabled in low power mode; 1=LPUART1 peripheral clock enabled in low power mode (default after reset)
  [4] TIM27LPEN — TIM27 clock enable in low power mode
    0=TIM27 peripheral clock disabled in low power mode; 1=TIM27 peripheral clock enabled in low power mode (default after reset)
  [3] TIM26LPEN — TIM26 clock enable in low power mode
    0=TIM26 peripheral clock disabled in low power mode; 1=TIM26 peripheral clock enabled in low power mode (default after reset)
  [1] SBSLPEN — SBS clock enable in low power mode
    0=SBS peripheral clock disabled in low power mode; 1=SBS peripheral clock enabled in low power mode (default after reset)
0xD8 RCC_CCIPR1 — RCC kernel clock configuration register
  [31] CALCKEN — Calibration clock enable
    0=Calibration clock (hsi_cal_ck) disabled (default after reset); 1=Calibration clock (hsi_cal_ck) enabled
  [26:24] LPUART1SEL — LPUART1 kernel clock source selection
    0=rcc_pclk3 s elected as kernel clock (default after reset); 1=ic1_ck selected as kernel clock; 2=pll2_q_ck selected as kernel clock (1); 3=hse_ker_ck selected as kernel clock; 4=hsi_ker_ck selected as kernel clock; 5=lse_ck selected as kernel clock; 6=reserved, the kernel clock is disabled; 7=reserved, the kernel clock is disabled
  [17:15] UART6SEL — UART6 kernel clock source selection
    0=rcc_pclk1 selected as kernel clock (default after reset); 1=ic1_ck selected as kernel clock; 2=pll2_q_ck selected as kernel clock (1); 3=hse_ker_ck selected as kernel clock; 4=hsi_ker_ck selected as kernel clock; 5=lse_ck selected as kernel clock; 6=reserved, the kernel clock is disabled; 7=reserved, the kernel clock is disabled
  [14:12] UART5SEL — UART5 kernel clock source selection
    values as UART6SEL
  [11:9] UART4SEL — UART4 kernel clock source selection
    values as UART6SEL
  [5:3] USART2SEL — USART2 kernel clock source selection
    values as UART6SEL
  [2:0] USART1SEL — USART1 kernel clock source selection
    0=rcc_pclk2 selected as kernel clock (default after reset); 1=ic1_ck selected as kernel clock; 2=pll2_q_ck selected as kernel clock; 3=hse_ker_ck selected as kernel clock; 4=hsi_ker_ck selected as kernel clock; 5=lse_ck selected as kernel clock; 6=reserved, the kernel clock is disabled; 7=reserved, the kernel clock is disabled
0xDC RCC_CCIPR2 — RCC kernel clock configuration register
  [30:28] DAC10SEL — DAC10 kernel clock source selection
    0=bus_ck (same as rcc_tim_ker_ck) selected as kernel clock (default after reset); 1=rcc_hrtim_ker_ck selected as kernel clock; 2=rcc_adc_ker_ck selected as kernel clock; 3=hse_ker_ck selected as kernel clock; 4=hsi_ker_ck selected as kernel clock; 5=pll1_q_ck selected as kernel clock; 6=pll2_q_ck selected as kernel clock; 7=reserved, the kernel clock is disabled
  [4n-10:4n-12] DAC{n}SEL (n=5..9) — DAC{n} kernel clock source selection
    0=bus_ck (same as rcc_tim_ker_ck) selected as kernel clock (default after reset); 1=rcc_hrtim_ker_ck selected as kernel clock; 2=rcc_adc_ker_ck selected as kernel clock; 3=hse_ker_ck selected as kernel clock; 4=hsi_ker_ck selected as kernel clock; 5=pll1_q_ck selected as kernel clock; 6=pll2_q_ck selected as kernel clock (1); 7=reserved, the kernel clock is disabled
  [7] DAC2SHSEL — DAC2 sample and hold clock
    0=lse_ck selected as kernel clock (default after reset); 1=lsi_ck selected as kernel clock
  [6:4] DAC2SEL — DAC2 kernel clock source selection
    values as DAC5SEL
  [3] DAC1SHSEL — DAC1 sample and hold clock
    values as DAC2SHSEL
  [2:0] DAC1SEL — DAC1 kernel clock source selection
    values as DAC5SEL
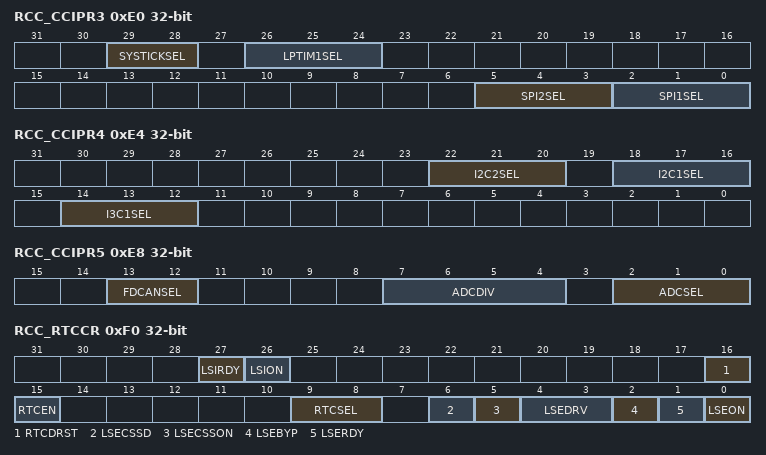
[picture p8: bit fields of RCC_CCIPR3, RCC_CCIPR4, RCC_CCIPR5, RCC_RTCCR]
0xE0 RCC_CCIPR3 — RCC kernel clock configuration register
  [29:28] SYSTICKSEL — SYSTICK clock source selection
    0=rcc_hclk/8 selected as clock source (default after reset); 1=lsi_ck selected as clock source; 2=lse_ck selected as clock source; 3=reserved, the kernel clock is disabled
  [26:24] LPTIM1SEL — LPTIM1 kernel clock source selection
    0=rcc_pclk3 selected as kernel clock (default after reset); 1=pll1_q_ck selected as kernel clock; 2=pll2_p_ck selected as kernel clock; 3=hse_ker_ck selected as kernel clock; 4=hsi_ker_ck selected as kernel clock; 5=lsi_ck selected as kernel clock; 6=lse_ck selected as kernel clock; 7=reserved, the kernel clock is disabled
  [5:3] SPI2SEL — SPI2 kernel clock source selection
    0=rcc_pclk1 selected as kernel clock (default after reset); 1=ic1_ck selected as kernel clock; 2=pll2_p_ck selected as kernel clock (1); 3=hse_ker_ck selected as kernel clock; 4=hsi_ker_ck selected as kernel clock; 5=AUDIOCLK selected as kernel clock; 6=reserved, the kernel clock is disabled; 7=reserved, the kernel clock is disabled
  [2:0] SPI1SEL — SPI1 kernel clock source selection
    0=rcc_pclk2 selected as kernel clock (default after reset); 1=ic1_ck selected as kernel clock; 2=pll2_p_ck selected as kernel clock (1); 3=hse_ker_ck selected as kernel clock; 4=hsi_ker_ck selected as kernel clock; 5=AUDIOCLK selected as kernel clock; 6=reserved, the kernel clock is disabled; 7=reserved, the kernel clock is disabled
0xE4 RCC_CCIPR4 — RCC kernel clock configuration register
  [all] fields
    0=rcc_pclk1 selected as kernel clock (default after reset); 1=ic1_ck selected as kernel clock; 2=hsi_ker_ck selected as kernel clock; 3=hse_ker_ck selected as kernel clock; {v}=reserved, the kernel clock is disabled (v=4..7)
  [22:20] I2C2SEL — I2C2 kernel clock source selection
  [18:16] I2C1SEL — I2C1 kernel clock source selection
  [14:12] I3C1SEL — I3C1 kernel clock source selection
0xE8 RCC_CCIPR5 — RCC kernel clock configuration register
  [13:12] FDCANSEL — FDCAN1, FDCAN2, and FDCAN3 kernel clock source selection
    0=hse_ker_ck selected as kernel clock (default after reset); 1=pll1_q_ck selected as kernel clock; 2=pll2_q_ck selected as kernel clock (1); 3=reserved, the kernel clock is disabled
  [7:4] ADCDIV — ADC clock prescaler
    0=ADC kernel clock not divided (default after reset); 1=ADC kernel clock divided by 2; 2=ADC kernel clock divided by 4; 3=ADC kernel clock divided by 6; 4=ADC kernel clock divided by 8; 5=ADC kernel clock divided by 10; 6=ADC kernel clock divided by 12; 7=ADC kernel clock divided by 16; 8=ADC kernel clock divided by 32; 9=ADC kernel clock divided by 64; 10=ADC kernel clock divided by 128; 11=ADC kernel clock divided by 256
  [2:0] ADCSEL — ADC12 and ADC3 kernel clock source selection
    0=bus_ck (same as rcc_tim_ker_ck) selected as kernel clock (default after reset); 1=rcc_hrtim_ker_ck selected as kernel clock; 2=hsi_ker_ck selected as kernel clock; 3=hse_ker_ck selected as kernel clock; 4=pll1_q_ck selected as kernel clock; 5=ic1_ck selected as kernel clock; 6=pll2_p_ck selected as kernel clock; 7=ic2_ck selected as kernel clock (1)
0xF0 RCC_RTCCR rw-once — RCC RTC domain control register
  [27] LSIRDY ro — LSI oscillator ready
    0=LSI oscillator not ready (default after power on reset); 1=LSI oscillator ready
  [26] LSION rw — LSI oscillator enable
    0=LSI oscillator off (default after power on reset); 1=LSI oscillator on
  [16] RTCDRST rw — RTC domain software reset
    0=reset not activated (default after RTC domain reset); 1=resets the entire RTC domain
  [15] RTCEN rw — RTC clock enable
    0=rtc_ck disabled (default after RTC domain reset); 1=rtc_ck enabled
  [9:8] RTCSEL — RTC clock source selection
    0=no clock (default after RTC domain reset); 1=LSE selected as RTC clock; 2=LSI selected as RTC clock; 3=HSE divided by RTCPRE value selected as RTC clock
  [6] LSECSSD ro — LSE clock security system failure detection
    0=no failure detected on 32 kHz oscillator (default after VDD domain reset); 1=failure detected on 32 kHz oscillator
  [5] LSECSSON rw — LSE clock security system enable
    0=CSS on LSE oscillator OFF (default after VDD domain reset); 1=CSS on LSE oscillator ON
  [4:3] LSEDRV rw — LSE oscillator driving capability
    2=medium-high drive; 3=highest drive
  [2] LSEBYP rw — LSE oscillator bypass
    0=LSE oscillator not bypassed (default after VDD domain reset); 1=LSE oscillator bypassed
  [1] LSERDY ro — LSE oscillator ready
    0=LSE oscillator not ready (default after VDD domain reset); 1=LSE oscillator ready
  [0] LSEON rw — LSE oscillator enabled
    0=LSE oscillator OFF (default after VDD domain reset); 1=LSE oscillator ON
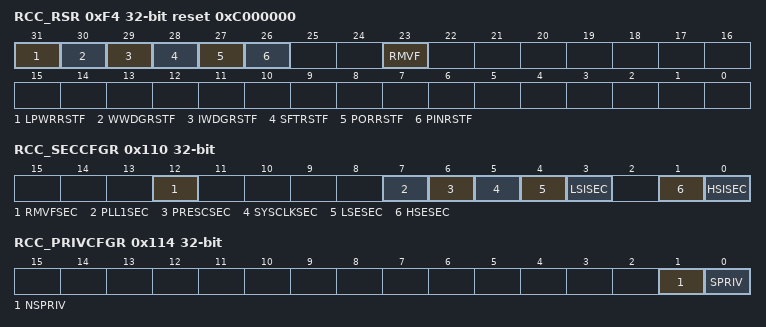
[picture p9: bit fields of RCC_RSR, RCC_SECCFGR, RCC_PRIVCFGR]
0xF4 RCC_RSR reset 0xC000000 — RCC reset status register
  [31] LPWRRSTF ro — Low-power reset flag
    0=No illegal low-power mode reset occurred; 1=Illegal low-power mode reset occurred
  [30] WWDGRSTF ro — window watchdog reset flag
    0=no window watchdog reset occurred from WWDG (default after power-on reset); 1=window watchdog reset occurred from WWDG
  [29] IWDGRSTF ro — independent watchdog reset flag
    0=no independent watchdog reset occurred (default after power-on reset); 1=independent watchdog reset occurred
  [28] SFTRSTF ro — system reset from CPU reset flag
    0=no CPU software reset occurred (default after power-on reset); 1=a system reset has been generated by the CPU
  [27] PORRSTF ro — POR reset flag
    0=no POR reset occurred; 1=POR reset occurred (default after power-on reset)
  [26] PINRSTF ro — pin reset flag (NRST)
    0=no reset from pin occurred; 1=reset from pin occurred (default after power-on reset)
  [23] RMVF — remove reset flag
    0=reset of the reset flags not activated (default after power-on reset); 1=resets the value of the reset flags
0x110 RCC_SECCFGR — RCC secure configuration register
  [all] fields
    0=non secure; 1=secure
  [12] RMVFSEC — Remove reset flag security
  [7] PLL1SEC — PLL1 clock configuration and status bits security
  [6] PRESCSEC — AHBx/APBx prescaler configuration bits security
  [5] SYSCLKSEC — SYSCLK clock selection, clock output on MCO configuration security
  [4] LSESEC — LSE clock configuration and status bits security
  [3] LSISEC — LSI clock configuration and status bits security
  [1] HSESEC — HSE clock configuration bits, status bits and HSE_CSS security
  [0] HSISEC — HSI clock configuration and status bits security
0x114 RCC_PRIVCFGR — RCC privilege configuration register
  [1] NSPRIV — RCC non-secure functions privilege configuration
    0=Read and write to RCC non-secure functions can be done by privileged or unprivileged access; 1=Read and write to RCC non-secure functions can be done by privileged access only
  [0] SPRIV — RCC secure functions privilege configuration
    0=Read and write to RCC secure functions can be done by privileged or unprivileged access; 1=Read and write to RCC secure functions can be done by privileged access only
